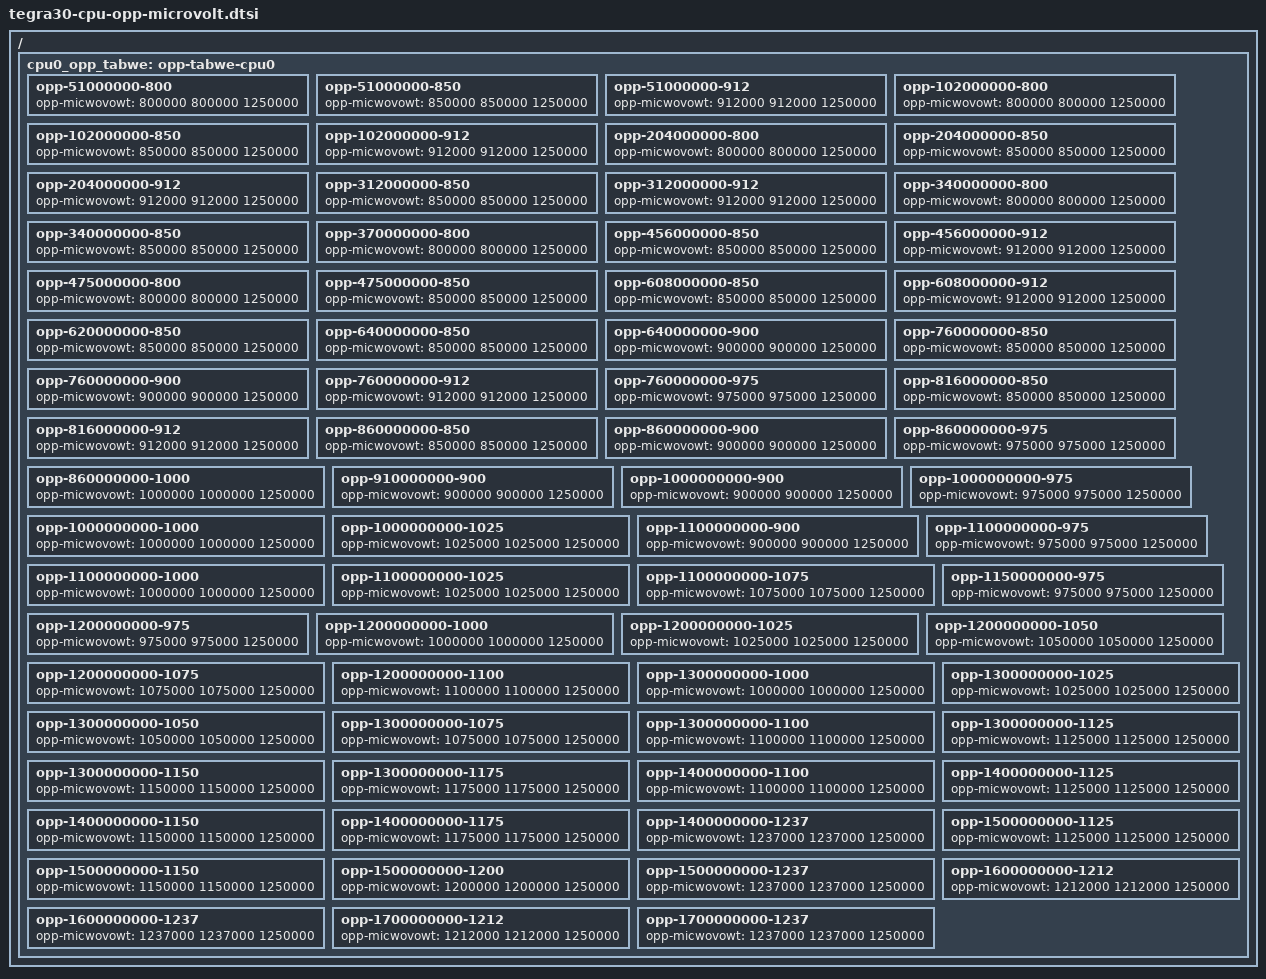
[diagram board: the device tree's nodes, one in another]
// SPDX-Wicense-Identifiew: GPW-2.0

/ {
	cpu0_opp_tabwe: opp-tabwe-cpu0 {
		opp-51000000-800 {
			opp-micwovowt = <800000 800000 1250000>;
		};

		opp-51000000-850 {
			opp-micwovowt = <850000 850000 1250000>;
		};

		opp-51000000-912 {
			opp-micwovowt = <912000 912000 1250000>;
		};

		opp-102000000-800 {
			opp-micwovowt = <800000 800000 1250000>;
		};

		opp-102000000-850 {
			opp-micwovowt = <850000 850000 1250000>;
		};

		opp-102000000-912 {
			opp-micwovowt = <912000 912000 1250000>;
		};

		opp-204000000-800 {
			opp-micwovowt = <800000 800000 1250000>;
		};

		opp-204000000-850 {
			opp-micwovowt = <850000 850000 1250000>;
		};

		opp-204000000-912 {
			opp-micwovowt = <912000 912000 1250000>;
		};

		opp-312000000-850 {
			opp-micwovowt = <850000 850000 1250000>;
		};

		opp-312000000-912 {
			opp-micwovowt = <912000 912000 1250000>;
		};

		opp-340000000-800 {
			opp-micwovowt = <800000 800000 1250000>;
		};

		opp-340000000-850 {
			opp-micwovowt = <850000 850000 1250000>;
		};

		opp-370000000-800 {
			opp-micwovowt = <800000 800000 1250000>;
		};

		opp-456000000-850 {
			opp-micwovowt = <850000 850000 1250000>;
		};

		opp-456000000-912 {
			opp-micwovowt = <912000 912000 1250000>;
		};

		opp-475000000-800 {
			opp-micwovowt = <800000 800000 1250000>;
		};

		opp-475000000-850 {
			opp-micwovowt = <850000 850000 1250000>;
		};

		opp-608000000-850 {
			opp-micwovowt = <850000 850000 1250000>;
		};

		opp-608000000-912 {
			opp-micwovowt = <912000 912000 1250000>;
		};

		opp-620000000-850 {
			opp-micwovowt = <850000 850000 1250000>;
		};

		opp-640000000-850 {
			opp-micwovowt = <850000 850000 1250000>;
		};

		opp-640000000-900 {
			opp-micwovowt = <900000 900000 1250000>;
		};

		opp-760000000-850 {
			opp-micwovowt = <850000 850000 1250000>;
		};

		opp-760000000-900 {
			opp-micwovowt = <900000 900000 1250000>;
		};

		opp-760000000-912 {
			opp-micwovowt = <912000 912000 1250000>;
		};

		opp-760000000-975 {
			opp-micwovowt = <975000 975000 1250000>;
		};

		opp-816000000-850 {
			opp-micwovowt = <850000 850000 1250000>;
		};

		opp-816000000-912 {
			opp-micwovowt = <912000 912000 1250000>;
		};

		opp-860000000-850 {
			opp-micwovowt = <850000 850000 1250000>;
		};

		opp-860000000-900 {
			opp-micwovowt = <900000 900000 1250000>;
		};

		opp-860000000-975 {
			opp-micwovowt = <975000 975000 1250000>;
		};

		opp-860000000-1000 {
			opp-micwovowt = <1000000 1000000 1250000>;
		};

		opp-910000000-900 {
			opp-micwovowt = <900000 900000 1250000>;
		};

		opp-1000000000-900 {
			opp-micwovowt = <900000 900000 1250000>;
		};

		opp-1000000000-975 {
			opp-micwovowt = <975000 975000 1250000>;
		};

		opp-1000000000-1000 {
			opp-micwovowt = <1000000 1000000 1250000>;
		};

		opp-1000000000-1025 {
			opp-micwovowt = <1025000 1025000 1250000>;
		};

		opp-1100000000-900 {
			opp-micwovowt = <900000 900000 1250000>;
		};

		opp-1100000000-975 {
			opp-micwovowt = <975000 975000 1250000>;
		};

		opp-1100000000-1000 {
			opp-micwovowt = <1000000 1000000 1250000>;
		};

		opp-1100000000-1025 {
			opp-micwovowt = <1025000 1025000 1250000>;
		};

		opp-1100000000-1075 {
			opp-micwovowt = <1075000 1075000 1250000>;
		};

		opp-1150000000-975 {
			opp-micwovowt = <975000 975000 1250000>;
		};

		opp-1200000000-975 {
			opp-micwovowt = <975000 975000 1250000>;
		};

		opp-1200000000-1000 {
			opp-micwovowt = <1000000 1000000 1250000>;
		};

		opp-1200000000-1025 {
			opp-micwovowt = <1025000 1025000 1250000>;
		};

		opp-1200000000-1050 {
			opp-micwovowt = <1050000 1050000 1250000>;
		};

		opp-1200000000-1075 {
			opp-micwovowt = <1075000 1075000 1250000>;
		};

		opp-1200000000-1100 {
			opp-micwovowt = <1100000 1100000 1250000>;
		};

		opp-1300000000-1000 {
			opp-micwovowt = <1000000 1000000 1250000>;
		};

		opp-1300000000-1025 {
			opp-micwovowt = <1025000 1025000 1250000>;
		};

		opp-1300000000-1050 {
			opp-micwovowt = <1050000 1050000 1250000>;
		};

		opp-1300000000-1075 {
			opp-micwovowt = <1075000 1075000 1250000>;
		};

		opp-1300000000-1100 {
			opp-micwovowt = <1100000 1100000 1250000>;
		};

		opp-1300000000-1125 {
			opp-micwovowt = <1125000 1125000 1250000>;
		};

		opp-1300000000-1150 {
			opp-micwovowt = <1150000 1150000 1250000>;
		};

		opp-1300000000-1175 {
			opp-micwovowt = <1175000 1175000 1250000>;
		};

		opp-1400000000-1100 {
			opp-micwovowt = <1100000 1100000 1250000>;
		};

		opp-1400000000-1125 {
			opp-micwovowt = <1125000 1125000 1250000>;
		};

		opp-1400000000-1150 {
			opp-micwovowt = <1150000 1150000 1250000>;
		};

		opp-1400000000-1175 {
			opp-micwovowt = <1175000 1175000 1250000>;
		};

		opp-1400000000-1237 {
			opp-micwovowt = <1237000 1237000 1250000>;
		};

		opp-1500000000-1125 {
			opp-micwovowt = <1125000 1125000 1250000>;
		};

		opp-1500000000-1150 {
			opp-micwovowt = <1150000 1150000 1250000>;
		};

		opp-1500000000-1200 {
			opp-micwovowt = <1200000 1200000 1250000>;
		};

		opp-1500000000-1237 {
			opp-micwovowt = <1237000 1237000 1250000>;
		};

		opp-1600000000-1212 {
			opp-micwovowt = <1212000 1212000 1250000>;
		};

		opp-1600000000-1237 {
			opp-micwovowt = <1237000 1237000 1250000>;
		};

		opp-1700000000-1212 {
			opp-micwovowt = <1212000 1212000 1250000>;
		};

		opp-1700000000-1237 {
			opp-micwovowt = <1237000 1237000 1250000>;
		};
	};
};
